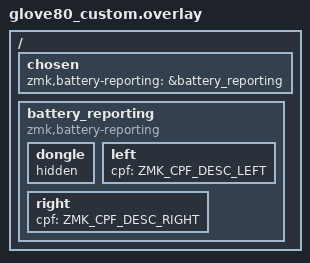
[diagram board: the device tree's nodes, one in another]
#include <dt-bindings/zmk/battery_reporting.h>

/ {
    chosen {
        zmk,battery-reporting = &battery_reporting;
    };

    battery_reporting: battery_reporting {
        compatible = "zmk,battery-reporting";

        dongle {
            hidden;
        };
        left {
            // display-name defaults to text version of `cpf` value.
            cpf = <ZMK_CPF_DESC_LEFT>;
        };
        right {
            cpf = <ZMK_CPF_DESC_RIGHT>;
        };
    };
};
